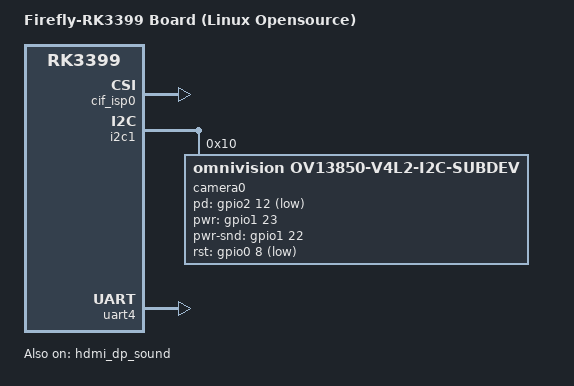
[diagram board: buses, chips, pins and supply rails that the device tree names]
/*
 * Copyright (c) 2016 Fuzhou Rockchip Electronics Co., Ltd
 *
 * This file is dual-licensed: you can use it either under the terms
 * of the GPL or the X11 license, at your option. Note that this dual
 * licensing only applies to this file, and not this project as a
 * whole.
 *
 *  a) This file is free software; you can redistribute it and/or
 *     modify it under the terms of the GNU General Public License as
 *     published by the Free Software Foundation; either version 2 of the
 *     License, or (at your option) any later version.
 *
 *     This file is distributed in the hope that it will be useful,
 *     but WITHOUT ANY WARRANTY; without even the implied warranty of
 *     MERCHANTABILITY or FITNESS FOR A PARTICULAR PURPOSE.  See the
 *     GNU General Public License for more details.
 *
 * Or, alternatively,
 *
 *  b) Permission is hereby granted, free of charge, to any person
 *     obtaining a copy of this software and associated documentation
 *     files (the "Software"), to deal in the Software without
 *     restriction, including without limitation the rights to use,
 *     copy, modify, merge, publish, distribute, sublicense, and/or
 *     sell copies of the Software, and to permit persons to whom the
 *     Software is furnished to do so, subject to the following
 *     conditions:
 *
 *     The above copyright notice and this permission notice shall be
 *     included in all copies or substantial portions of the Software.
 *
 *     THE SOFTWARE IS PROVIDED "AS IS", WITHOUT WARRANTY OF ANY KIND,
 *     EXPRESS OR IMPLIED, INCLUDING BUT NOT LIMITED TO THE WARRANTIES
 *     OF MERCHANTABILITY, FITNESS FOR A PARTICULAR PURPOSE AND
 *     NONINFRINGEMENT. IN NO EVENT SHALL THE AUTHORS OR COPYRIGHT
 *     HOLDERS BE LIABLE FOR ANY CLAIM, DAMAGES OR OTHER LIABILITY,
 *     WHETHER IN AN ACTION OF CONTRACT, TORT OR OTHERWISE, ARISING
 *     FROM, OUT OF OR IN CONNECTION WITH THE SOFTWARE OR THE USE OR
 *     OTHER DEALINGS IN THE SOFTWARE.
 */

/dts-v1/;

#include "rk3399-firefly-port.dtsi"

/ {
	model = "Firefly-RK3399 Board (Linux Opensource)";
	compatible = "rockchip,rk3399-firefly", "rockchip,rk3399";

	test-power {
		status = "okay";
	};
};

&cif_isp0 {
    rockchip,camera-modules-attached = <&camera0>;
    status = "okay";
};

&isp0_mmu {
    status = "okay";
};

&i2c1 {
	status = "okay";

	camera0: camera-module@10 {
		status = "okay";
		compatible = "omnivision,ov13850-v4l2-i2c-subdev";
		reg = < 0x10 >;
		device_type = "v4l2-i2c-subdev";

		clocks = <&cru SCLK_CIF_OUT>;
		clock-names = "clk_cif_out";

		pinctrl-names = "rockchip,camera_default", "rockchip,camera_sleep";
		pinctrl-0 = <&cam0_default_pins>;
		pinctrl-1 = <&cam0_sleep_pins>;

		rockchip,pd-gpio = <&gpio2 12 GPIO_ACTIVE_LOW>;
		rockchip,pwr-gpio = <&gpio1 23 GPIO_ACTIVE_HIGH>;
		rockchip,pwr-snd-gpio = <&gpio1 22 GPIO_ACTIVE_HIGH>;
		rockchip,rst-gpio = <&gpio0 8 GPIO_ACTIVE_LOW>;

		rockchip,camera-module-mclk-name = "clk_cif_out";
		rockchip,camera-module-facing = "back";
		rockchip,camera-module-name = "cmk-cb0695-fv1";
		rockchip,camera-module-len-name = "lg9569a2";
		rockchip,camera-module-fov-h = "66.0";
		rockchip,camera-module-fov-v = "50.1";
		rockchip,camera-module-orientation = <0>;
		rockchip,camera-module-iq-flip = <0>;
		rockchip,camera-module-iq-mirror = <0>;
		rockchip,camera-module-flip = <1>;
		rockchip,camera-module-mirror = <0>;

		rockchip,camera-module-defrect0 = <2112 1568 0 0 2112 1568>;
		rockchip,camera-module-defrect1 = <4224 3136 0 0 4224 3136>;
		rockchip,camera-module-defrect3 = <3264 2448 0 0 3264 2448>;
		rockchip,camera-module-flash-support = <0>;
		rockchip,camera-module-mipi-dphy-index = <0>;
	};
};

&hdmi_dp_sound {
	status = "okay";
};

&uart4 {
	status = "okay";
};

&dp_in_vopb {
	status = "disabled";
};

&hdmi_in_vopl {
	status = "disabled";
};

&wdt {
	status = "disabled";
};
